# CY8C4014SXI_420 register map
File version: 0.1
PSoC 4000
Registers are 32-bit, read-write, no defined reset value unless marked. A register's access mark holds for its fields unless they carry their own. Offsets are from the block's base; lines under a group give offsets from that group; [hi:lo] are bit positions; {n}, {i} and the like mark numbered series; 'fields as' and 'values as' point back to an identical list; <NAME> marks a mode.

## Memory map
0x00000000 I2C_Slave — Serial Communication Block

## I2C_Slave — Serial Communication Block
Base 0x00000000
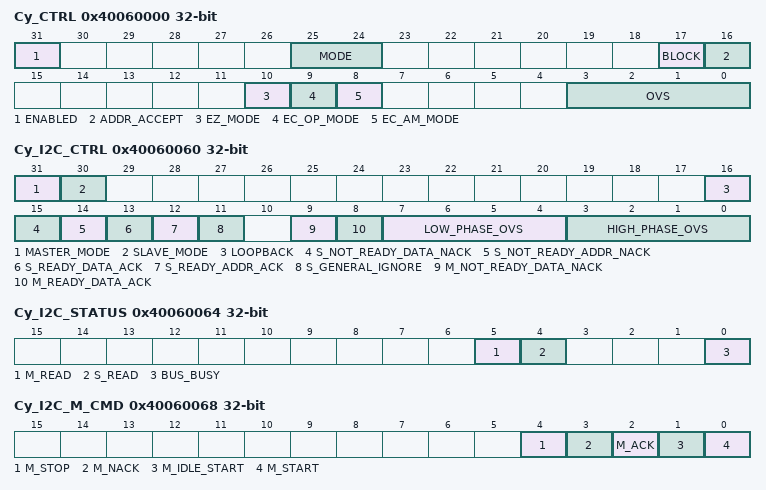
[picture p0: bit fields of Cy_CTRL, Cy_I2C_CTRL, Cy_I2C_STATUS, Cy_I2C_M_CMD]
0x40060000 Cy_CTRL — Generic control register
  [31] ENABLED — IP enabled ('1') or not ('0').
  [25:24] MODE — Mode of operation: I2C = 0, SPI = 1, UART = 2
  [17] BLOCK — If the externally clocked logic and the MMIO SW accesses to EZ memory coincide/collide, this bit determines whether a SW access should block and result in bus wait states ('BLOCK is 1') or not (BLOCK is '0')
  [16] ADDR_ACCEPT — Determines whether a received matching address is accepted in the RX FIFO ('1') or not ('0').his field is used in the I2C mode.
  [10] EZ_MODE — Non EZ mode ('0') or EZ mode ('1'). In EZ mode, a meta protocol is applied to the serial interface protocol.
  [9] EC_OP_MODE — Internally clocked mode ('0') or externally clocked mode ('1') operation. In internally clocked mode, the serial interface protocols run off the peripheral clock. In externally clocked mode, the serial interface protocols run off the clock as provided by the serial interface.
  [8] EC_AM_MODE — Internally clocked mode ('0') or externally clocked mode ('1') address matching (I2C) or selection (SPI).In internally clocked mode, the serial interface protocols run off the peripheral clock. In externally clocked mode, the serial interface protocols run off the clock as provided by the serial interface.
  [3:0] OVS — Serial interface bit period oversampling factor expressed in lP clock cycles. Used for SPI and UART functionality. OVS + 1 IP clock cycles constitute a single serial interface clock/bit cycle.
0x40060060 Cy_I2C_CTRL — I2C control register
  [31] MASTER_MODE — Master mode enabled ('1') or not ('0'). Note that both master and slave modes can be enabled at the same time. This allows the IP to address itself.
  [30] SLAVE_MODE — Slave mode enabled ('1') or not ('0').
  [16] LOOPBACK — Local loopback control
  [15] S_NOT_READY_DATA_NACK — When '1' a received data element byte the slave is immediately NACK'd when the receiver FIFO is full. When '1' clock stretching is performed (till the receiver FIFO is no longer full).
  [14] S_NOT_READY_ADDR_NACK — When '1', a received address by the slave is immediately ACK'd when the receiver FIFO is not full
  [13] S_READY_DATA_ACK — When '1', a received data element by the slave is immediately ACK'd when the receiver FIFO is not full
  [12] S_READY_ADDR_ACK — When '1', a received (matching) slave address is immediately ACK'd when the receiver FIFO is not full
  [11] S_GENERAL_IGNORE — When '1', a received general call slave address is immediately NACK'd (no ACK or clock stretching) and treated as a non matching slave address.
  [9] M_NOT_READY_DATA_NACK — When '1', a received data element byte the master is immediately NACK'd when the receiver FIFO is full. When '0', clock stretching is used instead (till the receiver FIFO is no longer full).
  [8] M_READY_DATA_ACK — When '1', a received data element by the master is immediately ACK'd when the receiver FIFO is not full.
  [7:4] LOW_PHASE_OVS — Serial I2C interface low phase oversampling factor. LOW_PHASE_OVS + 1 peripheral clock periods constitute the low phase of a bit period
  [3:0] HIGH_PHASE_OVS — Serial I2C interface high phase oversampling factor. HIGH_PHASE_OVS + 1 peripheral clock periods constitute the high phase of a bit period.
0x40060064 Cy_I2C_STATUS — I2C status register
  [5] M_READ ro — I2C master read transfer ('1') or I2C master write transfer ('0'). When the I2C master is inactive/idle or transmitting START, REPEATED START, STOP or an address, this field is '0''.
  [4] S_READ ro — I2C slave read transfer ('1') or I2C slave write transfer ('0'). When the I2C slave is inactive/idle or receiving START, REPEATED START, STOP or an address, this field is '0'.
  [0] BUS_BUSY ro — I2C bus is busy. The bus is considered busy ('1').
0x40060068 Cy_I2C_M_CMD — I2C master command register
  [4] M_STOP — When '1', attempt to transmit a STOP. When this action is performed, the hardware sets this field to '0'. This command has a higher priority than I2C_M_CMD.M_START: in situations where both a STOP and a REPEATED START could be transmitted, M_STOP takes precedence over M_START.
  [3] M_NACK — When '1', attempt to transmit a negative acknowledgement (NACK). When this action is performed, the hardware sets this field to '0'.
  [2] M_ACK — When '1', attempt to transmit an acknowledgement (ACK). When this action is performed, the hardware sets this field to '0'.
  [1] M_IDLE_START — When '1', transmit a START as soon as the bus is idle (I2C_STATUS.BUS_BUSY is '0', note that BUSY has a default value of '0'). When this action is performed, the hardware sets this field to '0'.
  [0] M_START — When '1', transmit a START or REPEATED START. Whether a START or REPEATED START is transmitted depends on the state of the master state machine. When this action is performed, the hardware sets this field to '0'.
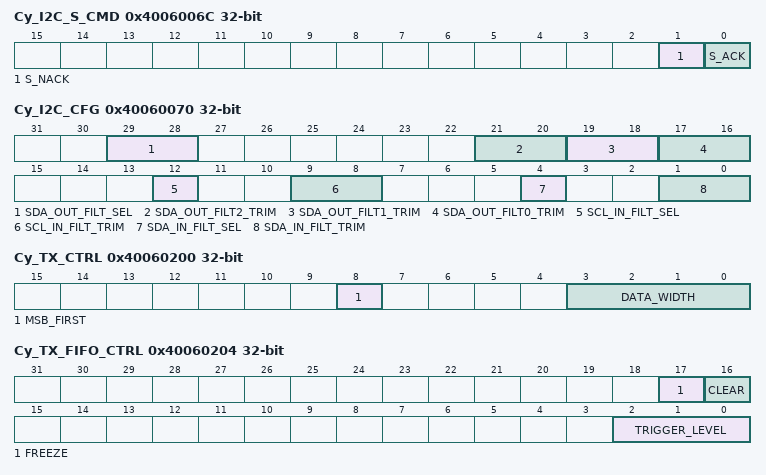
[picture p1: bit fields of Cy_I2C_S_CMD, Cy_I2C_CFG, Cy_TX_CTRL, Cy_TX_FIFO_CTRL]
0x4006006C Cy_I2C_S_CMD — I2C slave command register
  [1] S_NACK — When '1', attempt to transmit a negative acknowledgement (NACK). When this action is performed, the hardware sets this field to '0'
  [0] S_ACK — When '1', attempt to transmit an acknowledgement (ACK). When this action is performed, the hardware sets this field to '0'.
0x40060070 Cy_I2C_CFG — I2C fitler trimm register
  [29:28] SDA_OUT_FILT_SEL, [21:20] SDA_OUT_FILT2_TRIM, [19:18] SDA_OUT_FILT1_TRIM, [17:16] SDA_OUT_FILT0_TRIM, [12] SCL_IN_FILT_SEL, [9:8] SCL_IN_FILT_TRIM, [4] SDA_IN_FILT_SEL, [1:0] SDA_IN_FILT_TRIM
0x40060200 Cy_TX_CTRL — Transmitter control register
  [8] MSB_FIRST — Least significant bit first ('0') or most significant bit first ('1'). For I2C, this field should be '1'.
  [3:0] DATA_WIDTH — Data frame width. DATA_WIDTH + 1 is the amount of bits in a transmitted data frame.
0x40060204 Cy_TX_FIFO_CTRL — Transmitter FIFO control register
  [17] FREEZE — When '1', hardware reads from the transmitter FIFO do not remove FIFO entries. Freeze will not advance the TX FIFO read pointer.
  [16] CLEAR — When '1', the transmitter FIFO and transmitter shift register are cleared/invalidated. Invalidation will last for as long as this field is '1'. If a quick clear/invalidation is required, the field should be set to '1' and be followed by a set to '0'. If a clear/invalidation is required for an extended time period, the field should be set to '1' during the complete time period.
  [2:0] TRIGGER_LEVEL — Trigger level. When the transmitter FIFO has less entries than the amount of this field, a transmitter trigger event is generated.
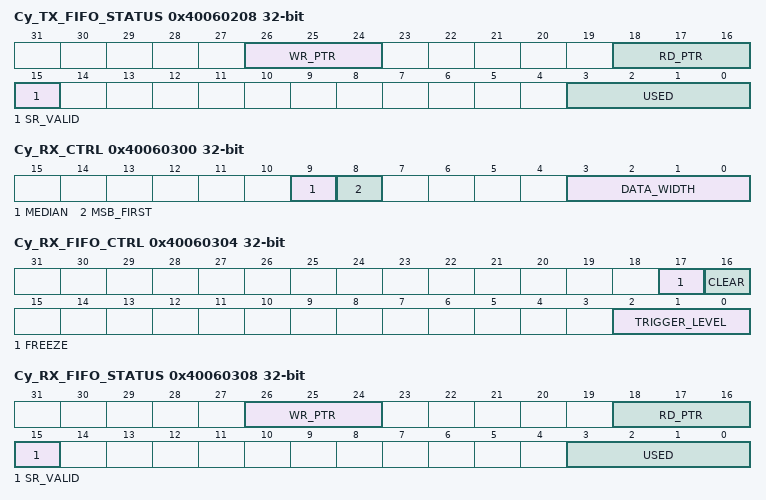
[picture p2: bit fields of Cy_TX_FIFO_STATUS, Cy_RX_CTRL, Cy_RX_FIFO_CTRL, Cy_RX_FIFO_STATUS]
0x40060208 Cy_TX_FIFO_STATUS — Transmitter FIFO status register
  [26:24] WR_PTR ro — FIFO write pointer: FIFO location at which a new data frame is written.
  [18:16] RD_PTR ro — FIFO read pointer: FIFO location from which a data frame is read by the hardware.
  [15] SR_VALID ro — Indicates whether the TX shift registers holds a valid data frame ('1') or not ('0')
  [3:0] USED ro — Amount of entries in the transmitter FIFO. The value of this field ranges from 0 to 8.
0x40060240 Cy_TX_FIFO_WR — Transmitter FIFO write register
  [15:0] DATA wo — Data frame written into the transmitter FIFO. Behavior is similar to that of a PUSH operation.
0x40060300 Cy_RX_CTRL — Receiver control register
  [9] MEDIAN — Median filter. When '1', a digital 3 taps median filter is performed on input interface lines.
  [8] MSB_FIRST — Least significant bit first ('0') or most significant bit first ('1').
  [3:0] DATA_WIDTH — Data frame width. DATA_WIDTH + 1 is the expected amount of bits in received data frame.
0x40060304 Cy_RX_FIFO_CTRL — Receiver FIFO control register
  [17] FREEZE — When '1', hardware writes to the receiver FIFO have no effect. Freeze will not advance the RX FIFO write pointer.
  [16] CLEAR — When '1', the receiver FIFO and receiver shift register are cleared/invalidated. Invalidation will last for as long as this field is '1'. If a quick clear/invalidation is required, the field should be set to '1' and be followed by a set to '0'. If a clear/invalidation is required for an extended time period, the field should be set to '1' during the complete time period.
  [2:0] TRIGGER_LEVEL — Trigger level. When the receiver FIFO has more entries than the amount of this field, a receiver trigger event is generated.
0x40060308 Cy_RX_FIFO_STATUS — Receiver FIFO status registerS
  [26:24] WR_PTR ro — FIFO write pointer: FIFO location at which a new data frame is written by the hardware.
  [18:16] RD_PTR ro — FIFO read pointer: FIFO location from which a data frame is read.
  [15] SR_VALID ro — Indicates whether the RX shift registers holds a (partial) valid data frame ('1') or not ('0').
  [3:0] USED ro — Amount of entries in the receiver FIFO. The value of this field ranges from 0 to 8.
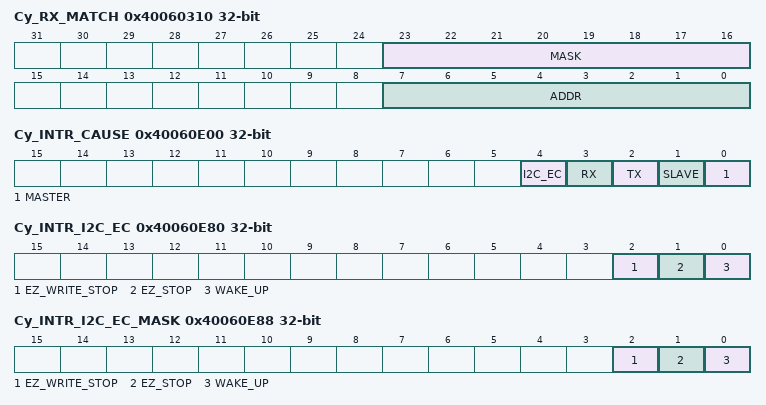
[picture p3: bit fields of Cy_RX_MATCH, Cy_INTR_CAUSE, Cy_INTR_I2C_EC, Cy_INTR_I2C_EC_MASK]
0x40060310 Cy_RX_MATCH — Slave address and mask register
  [23:16] MASK — Slave device address mask. This field is a 8 bit mask that specifies which of the ADDR field bits in the SCB_RX_MATCH_ADDR register take part in the matching of the slave address.
  [7:0] ADDR — Slave device address. For UART multi-processor mode all eight bits a reused. For I2C, bit 0 of the register is not used.
0x40060340 Cy_RX_FIFO_RD — Receiver FIFO read register
  [15:0] DATA ro — Data read from the receiver FIFO. Reading a data frame will remove the data frame from the FIFO.
0x40060E00 Cy_INTR_CAUSE — Interrupt cause register
  [4] I2C_EC ro — Externally clock I2C interrupt active.
  [3] RX ro — Receiver interrupt active.
  [2] TX ro — Transmitter interrupt active.
  [1] SLAVE ro — Slave interrupt active.
  [0] MASTER ro — Master interrupt active.
0x40060E80 Cy_INTR_I2C_EC — Externally clocked I2C interrupt request register
  [2] EZ_WRITE_STOP — STOP detection after a write transfer occurred (only available in EZ mode). Active on detected STOP.
  [1] EZ_STOP — STOP detection (only available in EZ mode). Active on detected STOP. Only used in EZ mode and when EC_OP is '1'.
  [0] WAKE_UP — Wake up request. Active on incoming slave request (with address match). Only used when EC_AM is '1'.
0x40060E88 Cy_INTR_I2C_EC_MASK — Externally clocked I2C interrupt mask register
  [2] EZ_WRITE_STOP — Mask bit for corresponding bit in interrupt request register.
  [1] EZ_STOP — Mask bit for corresponding bit in interrupt request register.
  [0] WAKE_UP — Mask bit for corresponding bit in interrupt request register.
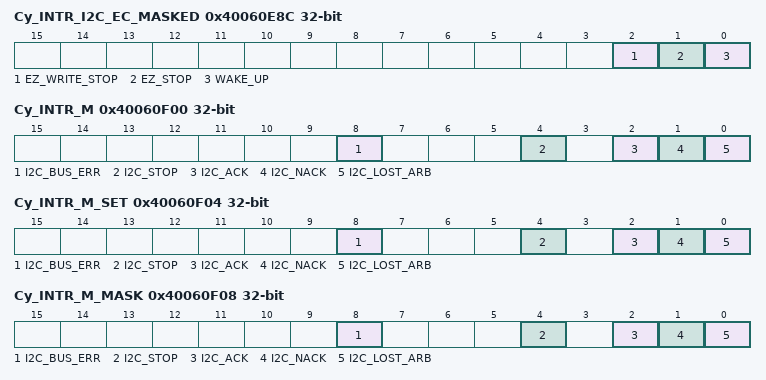
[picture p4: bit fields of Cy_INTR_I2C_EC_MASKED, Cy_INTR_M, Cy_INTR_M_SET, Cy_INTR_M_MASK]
0x40060E8C Cy_INTR_I2C_EC_MASKED — Externally clocked I2C interrupt masked register
  [2] EZ_WRITE_STOP — Logical and of corresponding request and mask bits.
  [1] EZ_STOP — Logical and of corresponding request and mask bits.
  [0] WAKE_UP — Logical and of corresponding request and mask bits.
0x40060F00 Cy_INTR_M — Master interrupt request register
  [8] I2C_BUS_ERR — I2C master bus error (unexpected detection of START or STOP condition).
  [4] I2C_STOP — I2C master STOP. Set to '1', when the master has transmitted a STOP.
  [2] I2C_ACK — I2C master acknowledgement. Set to '1', when the master receives a ACK (typically after the master transmitted the slave address or TX data).
  [1] I2C_NACK — I2C master negative acknowledgement. Set to '1', when the master receives a NACK (typically after the master transmitted the slave address or TX data).
  [0] I2C_LOST_ARB — I2C master lost arbitration: the value driven by the master on the SDA line is not the same as the value observed on the SDA line.
0x40060F04 Cy_INTR_M_SET — Master interrupt set request register
  [8] I2C_BUS_ERR — Write with '1' to set corresponding bit in interrupt request register.
  [4] I2C_STOP — Write with '1' to set corresponding bit in interrupt request register.
  [2] I2C_ACK — Write with '1' to set corresponding bit in interrupt request register.
  [1] I2C_NACK — Write with '1' to set corresponding bit in interrupt request register.
  [0] I2C_LOST_ARB — Write with '1' to set corresponding bit in interrupt request register.
0x40060F08 Cy_INTR_M_MASK — Master interrupt mask register
  [8] I2C_BUS_ERR — Mask bit for corresponding bit in interrupt request register.
  [4] I2C_STOP — Mask bit for corresponding bit in interrupt request register.
  [2] I2C_ACK — Mask bit for corresponding bit in interrupt request register.
  [1] I2C_NACK — Mask bit for corresponding bit in interrupt request register.
  [0] I2C_LOST_ARB — Mask bit for corresponding bit in interrupt request register.
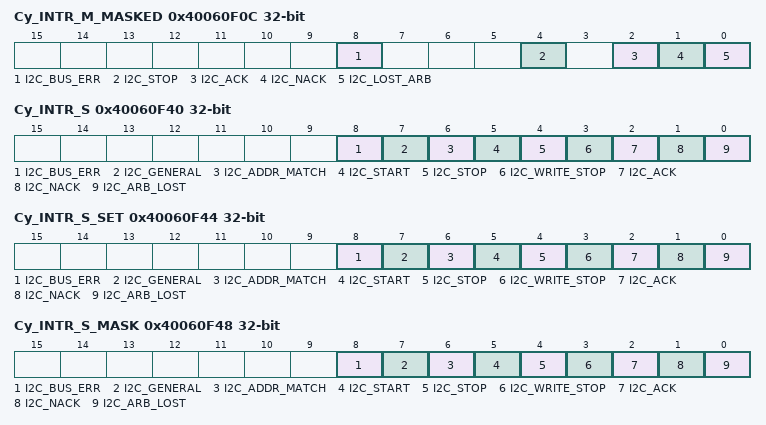
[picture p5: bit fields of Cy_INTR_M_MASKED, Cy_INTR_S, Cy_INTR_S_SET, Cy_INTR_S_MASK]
0x40060F0C Cy_INTR_M_MASKED — Master interrupt masked request register
  [8] I2C_BUS_ERR — Logical and of corresponding request and mask bits.
  [4] I2C_STOP — Logical and of corresponding request and mask bits.
  [2] I2C_ACK — Logical and of corresponding request and mask bits.
  [1] I2C_NACK — Logical and of corresponding request and mask bits.
  [0] I2C_LOST_ARB — Logical and of corresponding request and mask bits.
0x40060F40 Cy_INTR_S — Slave interrupt request register
  [8] I2C_BUS_ERR — I2C slave bus error (unexpected detection of START or STOP condition).
  [7] I2C_GENERAL — I2C slave general call address received. If CTRL.ADDR_ACCEPT, the received address 0x00 (including the R/W bit) is available in the RX FIFO
  [6] I2C_ADDR_MATCH — I2C slave matching address received. If CTRL.ADDR_ACCEPT, the received address (including the R/W bit) is available in the RX FIFO.
  [5] I2C_START — I2C slave START received. Set to '1', when START or REPEATED START event is detected.
  [4] I2C_STOP — I2C STOP event for I2C (read or write) transfer intended for this slave (address matching is performed). Set to '1', when STOP or REPEATED START event is detected
  [3] I2C_WRITE_STOP — I2C STOP event for I2C write transfer intended for this slave (address matching is performed).Set to '1', when STOP or REPEATED START event is detected.
  [2] I2C_ACK — I2C slave acknowledgement received. Set to '1', when the slave receives a ACK (typically after the slave transmitted TX data).
  [1] I2C_NACK — I2C slave negative acknowledgement received. Set to '1', when the slave receives a NACK (typically after the slave transmitted TX data).
  [0] I2C_ARB_LOST — I2C slave lost arbitration: the value driven on the SDA line is not the same as the value observed on the SDA line (while the SCL line is '1').
0x40060F44 Cy_INTR_S_SET — Slave interrupt set request register
  [8] I2C_BUS_ERR — Write with '1' to set corresponding bit in interrupt request register.
  [7] I2C_GENERAL — Write with '1' to set corresponding bit in interrupt request register.
  [6] I2C_ADDR_MATCH — Write with '1' to set corresponding bit in interrupt request register.
  [5] I2C_START — Write with '1' to set corresponding bit in interrupt request register.
  [4] I2C_STOP — Write with '1' to set corresponding bit in interrupt request register.
  [3] I2C_WRITE_STOP — Write with '1' to set corresponding bit in interrupt request register.
  [2] I2C_ACK — Write with '1' to set corresponding bit in interrupt request register.
  [1] I2C_NACK — Write with '1' to set corresponding bit in interrupt request register.
  [0] I2C_ARB_LOST — Write with '1' to set corresponding bit in interrupt request register.
0x40060F48 Cy_INTR_S_MASK — Slave interrupt mask register
  [8] I2C_BUS_ERR — Mask bit for corresponding bit in interrupt request register.
  [7] I2C_GENERAL — Mask bit for corresponding bit in interrupt request register.
  [6] I2C_ADDR_MATCH — Mask bit for corresponding bit in interrupt request register.
  [5] I2C_START — Mask bit for corresponding bit in interrupt request register.
  [4] I2C_STOP — Mask bit for corresponding bit in interrupt request register.
  [3] I2C_WRITE_STOP — Mask bit for corresponding bit in interrupt request register.
  [2] I2C_ACK — Mask bit for corresponding bit in interrupt request register.
  [1] I2C_NACK — Mask bit for corresponding bit in interrupt request register.
  [0] I2C_ARB_LOST — Mask bit for corresponding bit in interrupt request register.
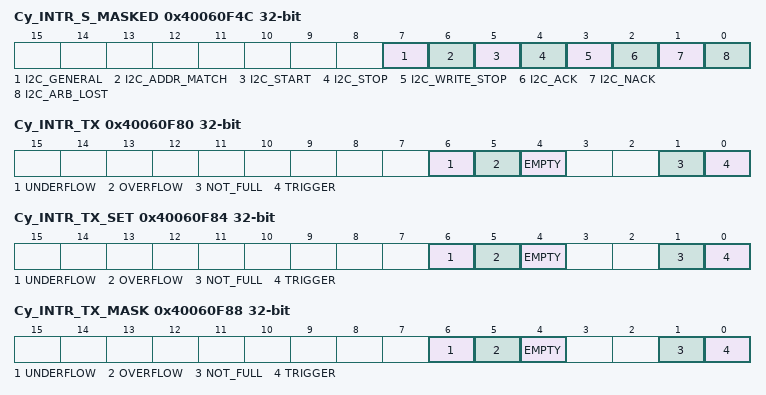
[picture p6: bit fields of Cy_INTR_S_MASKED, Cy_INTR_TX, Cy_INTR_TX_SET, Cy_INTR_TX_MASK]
0x40060F4C Cy_INTR_S_MASKED — Slave interrupt masked register
  [7] I2C_GENERAL — Logical and of corresponding request and mask bits.
  [6] I2C_ADDR_MATCH — Logical and of corresponding request and mask bits.
  [5] I2C_START — Logical and of corresponding request and mask bits.
  [4] I2C_STOP — Logical and of corresponding request and mask bits.
  [3] I2C_WRITE_STOP — Logical and of corresponding request and mask bits.
  [2] I2C_ACK — Logical and of corresponding request and mask bits.
  [1] I2C_NACK — Logical and of corresponding request and mask bits.
  [0] I2C_ARB_LOST — Logical and of corresponding request and mask bits.
0x40060F80 Cy_INTR_TX — Transmitter interrupt request register
  [6] UNDERFLOW — Attempt to read from an empty TX FIFO.
  [5] OVERFLOW — Attempt to write to a full TX FIFO.
  [4] EMPTY — TX FIFO is empty; i.e. it has 0 entries.
  [1] NOT_FULL — TX FIFO is not full.
  [0] TRIGGER — Less entries in the TX FIFO than the value specified by TRIGGER_LEVEL in SCB_TX_FIFO_CTL.
0x40060F84 Cy_INTR_TX_SET — Transmitter interrupt set request register
  [6] UNDERFLOW — Write with '1' to set corresponding bit in interrupt request register.
  [5] OVERFLOW — Write with '1' to set corresponding bit in interrupt request register.
  [4] EMPTY — Write with '1' to set corresponding bit in interrupt request register.
  [1] NOT_FULL — Write with '1' to set corresponding bit in interrupt request register.
  [0] TRIGGER — Write with '1' to set corresponding bit in interrupt request register.
0x40060F88 Cy_INTR_TX_MASK — Transmitter interrupt mask request register
  [6] UNDERFLOW — Mask bit for corresponding bit in interrupt request register.
  [5] OVERFLOW — Mask bit for corresponding bit in interrupt request register.
  [4] EMPTY — Mask bit for corresponding bit in interrupt request register.
  [1] NOT_FULL — Mask bit for corresponding bit in interrupt request register.
  [0] TRIGGER — Mask bit for corresponding bit in interrupt request register.
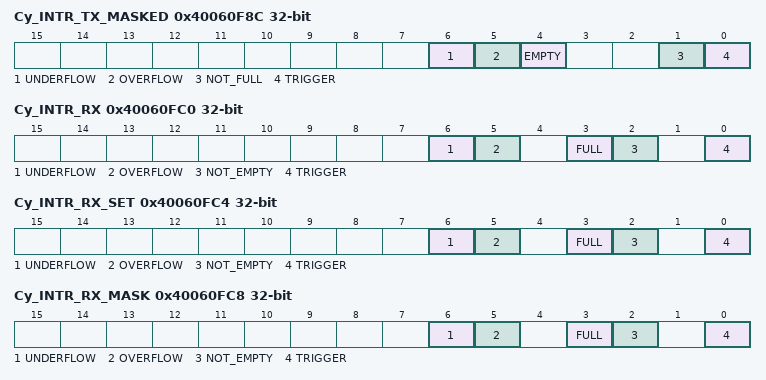
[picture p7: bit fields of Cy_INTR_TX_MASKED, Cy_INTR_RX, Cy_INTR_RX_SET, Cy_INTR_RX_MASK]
0x40060F8C Cy_INTR_TX_MASKED — Transmitter interrupt masked request register
  [6] UNDERFLOW — Logical and of corresponding request and mask bits.
  [5] OVERFLOW — Logical and of corresponding request and mask bits.
  [4] EMPTY — Logical and of corresponding request and mask bits.
  [1] NOT_FULL — Logical and of corresponding request and mask bits.
  [0] TRIGGER — Logical and of corresponding request and mask bits.
0x40060FC0 Cy_INTR_RX — Receiver interrupt request register
  [6] UNDERFLOW — Attempt to read from an empty RX FIFO.
  [5] OVERFLOW — Attempt to write to a full RX FIFO. Note: in I2C mode, the OVERFLOW is set when a data frame is received and the RX FIFO is full, independent of whether it is ACK'd or NACK'd.
  [3] FULL — RX FIFO is full. Note that received data frames are lost when the RX FIFO is full.
  [2] NOT_EMPTY — RX FIFO is not empty.
  [0] TRIGGER — More entries in the RX FIFO than the value specified by TRIGGER_LEVEL in SCB_RX_FIFO_CTL.
0x40060FC4 Cy_INTR_RX_SET — Receiver interrupt set request register
  [6] UNDERFLOW — Write with '1' to set corresponding bit in interrupt request register.
  [5] OVERFLOW — Write with '1' to set corresponding bit in interrupt request register.
  [3] FULL — Write with '1' to set corresponding bit in interrupt request register.
  [2] NOT_EMPTY — Write with '1' to set corresponding bit in interrupt request register.
  [0] TRIGGER — Write with '1' to set corresponding bit in interrupt request register.
0x40060FC8 Cy_INTR_RX_MASK — Receiver interrupt mask register
  [6] UNDERFLOW — Mask bit for corresponding bit in interrupt request register.
  [5] OVERFLOW — Mask bit for corresponding bit in interrupt request register.
  [3] FULL — Mask bit for corresponding bit in interrupt request register.
  [2] NOT_EMPTY — Mask bit for corresponding bit in interrupt request register.
  [0] TRIGGER — Mask bit for corresponding bit in interrupt request register.
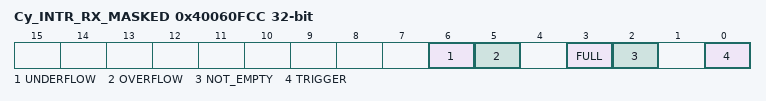
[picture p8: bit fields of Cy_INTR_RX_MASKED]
0x40060FCC Cy_INTR_RX_MASKED — Receiver interrupt masked register
  [6] UNDERFLOW — Logical and of corresponding request and mask bits.
  [5] OVERFLOW — Logical and of corresponding request and mask bits.
  [3] FULL — Logical and of corresponding request and mask bits.
  [2] NOT_EMPTY — Logical and of corresponding request and mask bits.
  [0] TRIGGER — Logical and of corresponding request and mask bits.
